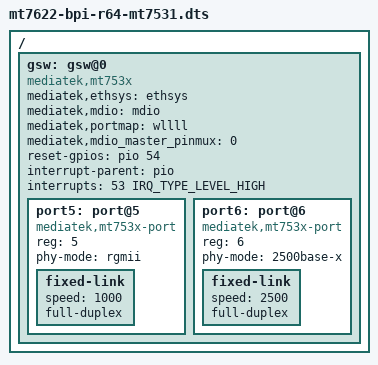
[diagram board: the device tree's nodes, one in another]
/*
 * Copyright (c) 2018 MediaTek Inc.
 * Author: Ryder Lee <ryder.lee@mediatek.com>
 *
 * SPDX-License-Identifier: (GPL-2.0 OR MIT)
 */

/dts-v1/;

#include "mt7622-bananapi-bpi-r64.dts"

/ {
	gsw: gsw@0 {
		compatible = "mediatek,mt753x";
		mediatek,ethsys = <&ethsys>;
		#address-cells = <1>;
		#size-cells = <0>;
	};
};

&gsw {
	mediatek,mdio = <&mdio>;
	mediatek,portmap = "wllll";
	mediatek,mdio_master_pinmux = <0>;
	reset-gpios = <&pio 54 0>;
	interrupt-parent = <&pio>;
	interrupts = <53 IRQ_TYPE_LEVEL_HIGH>;
	status = "okay";

	port5: port@5 {
		compatible = "mediatek,mt753x-port";
		reg = <5>;
		phy-mode = "rgmii";
		fixed-link {
			speed = <1000>;
			full-duplex;
		};
	};

	port6: port@6 {
		compatible = "mediatek,mt753x-port";
		reg = <6>;
		phy-mode = "2500base-x";
		fixed-link {
			speed = <2500>;
			full-duplex;
		};
	};
};
